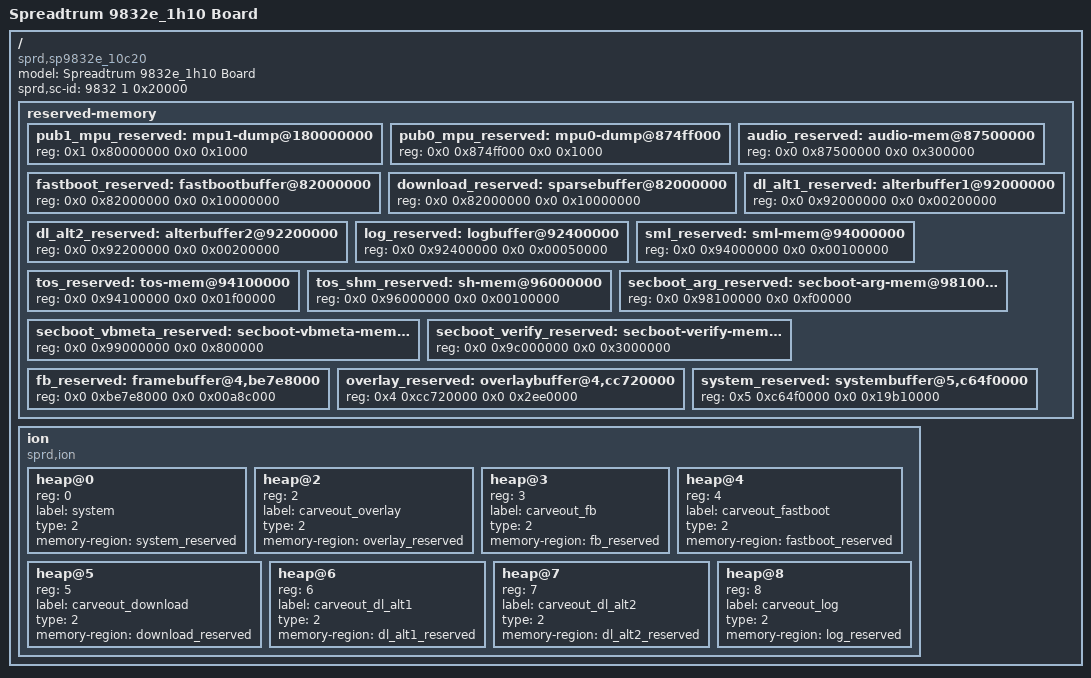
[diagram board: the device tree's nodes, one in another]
/*
 * Spreadtrum SP9860g board DTS file
 *
 * Copyright (C) 2016, Spreadtrum Communications Inc.
 *
 * This file is licensed under a dual GPLv2 or X11 license.
 */

/dts-v1/;

/ {
	model = "Spreadtrum 9832e_1h10 Board";

	compatible = "sprd,sp9832e_10c20";

	sprd,sc-id = <9832 1 0x20000>;

	reserved-memory {
		#address-cells = <2>;
		#size-cells = <2>;
		ranges;

		pub1_mpu_reserved: mpu1-dump@180000000 {
			reg = <0x1 0x80000000 0x0 0x1000>;
		};

		pub0_mpu_reserved: mpu0-dump@874ff000 {
			reg = <0x0 0x874ff000 0x0 0x1000>;
		};

		audio_reserved: audio-mem@87500000 {
			reg = <0x0 0x87500000 0x0 0x300000>;
		};

		fastboot_reserved: fastbootbuffer@82000000{
			reg = <0x0 0x82000000 0x0 0x10000000>;
		};

		download_reserved: sparsebuffer@82000000{
			reg = <0x0 0x82000000 0x0 0x10000000>;
		};

		dl_alt1_reserved: alterbuffer1@92000000{
			reg = <0x0 0x92000000 0x0 0x00200000>;
		};

		dl_alt2_reserved: alterbuffer2@92200000{
			reg = <0x0 0x92200000 0x0 0x00200000>;
		};

		log_reserved: logbuffer@92400000{
			reg = <0x0 0x92400000 0x0 0x00050000>;
		};

		/* must be 4K aligned */
		sml_reserved: sml-mem@94000000{
			reg = <0x0 0x94000000 0x0 0x00100000>;
		};

		tos_reserved: tos-mem@94100000{
			reg = <0x0 0x94100000 0x0 0x01f00000>;
		};

		tos_shm_reserved: sh-mem@96000000{
			reg = <0x0 0x96000000 0x0 0x00100000>;
		};

		secboot_arg_reserved: secboot-arg-mem@98100000{
			reg = <0x0 0x98100000 0x0 0xf00000>;
		};

		secboot_vbmeta_reserved: secboot-vbmeta-mem@99000000{
			reg = <0x0 0x99000000 0x0 0x800000>;
		};

		secboot_verify_reserved: secboot-verify-mem@9c000000{
			reg = <0x0 0x9c000000 0x0 0x3000000>;
		};

		fb_reserved: framebuffer@4,be7e8000{
			reg = <0x0 0xbe7e8000 0x0 0x00a8c000>;
		};

		overlay_reserved: overlaybuffer@4,cc720000{
			reg = <0x4 0xcc720000 0x0 0x2ee0000>;
		};

		system_reserved: systembuffer@5,c64f0000{
			reg = <0x5 0xc64f0000 0x0 0x19b10000>;
		};
	};


	ion {
		compatible = "sprd,ion";
		#address-cells = <1>;
		#size-cells = <0>;

		heap@0 {
			reg = <0>;
			label = "system";
			type = <2>;
			memory-region = <&system_reserved>;
		};

		heap@2 {
			reg = <2>;
			label = "carveout_overlay";
			type = <2>;
			memory-region = <&overlay_reserved>;
		};

		heap@3 {
			reg = <3>;
			label = "carveout_fb";
			type = <2>;
			memory-region = <&fb_reserved>;
		};

		heap@4 {
			reg = <4>;
			label = "carveout_fastboot";
			type = <2>;
			memory-region = <&fastboot_reserved>;
		};

		heap@5 {
			reg = <5>;
			label = "carveout_download";
			type = <2>;
			memory-region = <&download_reserved>;
		};

		heap@6 {
			reg = <6>;
			label = "carveout_dl_alt1";
			type = <2>;
			memory-region = <&dl_alt1_reserved>;
		};

		heap@7 {
			reg = <7>;
			label = "carveout_dl_alt2";
			type = <2>;
			memory-region = <&dl_alt2_reserved>;
		};

		heap@8 {
			reg = <8>;
			label = "carveout_log";
			type = <2>;
			memory-region = <&log_reserved>;
		};
	};
};
